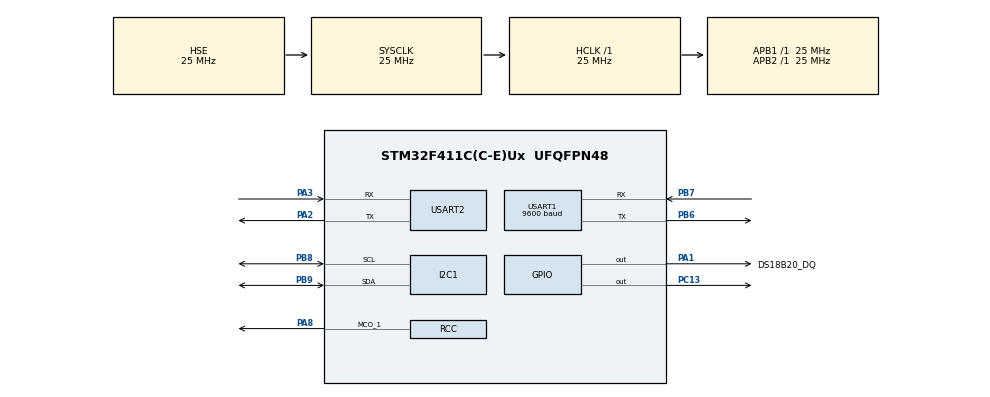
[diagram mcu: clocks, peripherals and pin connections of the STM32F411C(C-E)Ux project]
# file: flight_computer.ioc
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Mcu.Family=STM32F4
Mcu.Name=STM32F411C(C-E)Ux
Mcu.Package=UFQFPN48
NVIC.PriorityGroup=NVIC_PRIORITYGROUP_4
NVIC.USART1_IRQn=true\:5\:0\:false\:false\:true\:true\:true\:true
PA1.GPIO_Label=DS18B20_DQ
PA1.GPIO_ModeDefaultOutputPP=GPIO_MODE_OUTPUT_OD
PA1.GPIO_PuPd=GPIO_NOPULL
PA1.PinState=GPIO_PIN_SET
PA1.Signal=GPIO_Output
PA13.Mode=Serial_Wire
PA13.Signal=SYS_JTMS-SWDIO
PA14.Mode=Serial_Wire
PA14.Signal=SYS_JTCK-SWCLK
PA2.Mode=Asynchronous
PA2.Signal=USART2_TX
PA3.Mode=Asynchronous
PA3.Signal=USART2_RX
PA8.Mode=Clock-out-1
PA8.Signal=RCC_MCO_1
PB6.Mode=Asynchronous
PB6.Signal=USART1_TX
PB7.Mode=Asynchronous
PB7.Signal=USART1_RX
PB8.Mode=I2C
PB8.Signal=I2C1_SCL
PB9.Mode=I2C
PB9.Signal=I2C1_SDA
PC13-ANTI_TAMP.Signal=GPIO_Output
PC14-OSC32_IN.Mode=LSE-External-Oscillator
PC14-OSC32_IN.Signal=RCC_OSC32_IN
PC15-OSC32_OUT.Mode=LSE-External-Oscillator
PC15-OSC32_OUT.Signal=RCC_OSC32_OUT
PH0\ -\ OSC_IN.Mode=HSE-External-Oscillator
PH0\ -\ OSC_IN.Signal=RCC_OSC_IN
PH1\ -\ OSC_OUT.Mode=HSE-External-Oscillator
PH1\ -\ OSC_OUT.Signal=RCC_OSC_OUT
ProjectManager.HeapSize=0x200
ProjectManager.StackSize=0x400
ProjectManager.TargetToolchain=CMake
RCC.AHBFreq_Value=25000000
RCC.APB1Freq_Value=25000000
RCC.APB1TimFreq_Value=25000000
RCC.APB2Freq_Value=25000000
RCC.APB2TimFreq_Value=25000000
RCC.CortexFreq_Value=25000000
RCC.HCLKFreq_Value=25000000
RCC.HSE_VALUE=25000000
RCC.HSI_VALUE=16000000
RCC.RCC_MCO1Source=RCC_MCO1SOURCE_HSE
RCC.RCC_MCODiv1=RCC_MCODIV_3
RCC.RCC_RTC_Clock_Source=RCC_RTCCLKSOURCE_LSE
RCC.RCC_RTC_Clock_SourceVirtual=RCC_RTCCLKSOURCE_LSE
RCC.SYSCLKFreq_VALUE=25000000
RCC.SYSCLKSource=RCC_SYSCLKSOURCE_HSE
RCC.VCOOutputFreq_Value=192000000
USART1.BaudRate=9600
USART1.VirtualMode=VM_ASYNC
USART2.VirtualMode=VM_ASYNC
VP_RTC_VS_RTC_Activate.Mode=RTC_Enabled
board=custom

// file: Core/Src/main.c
/* USER CODE BEGIN Header */
/**
  ******************************************************************************
  * @file           : main.c
  * @brief          : ASTRA Flight Computer entry point
  ******************************************************************************
  * @attention
  *
  * Copyright (c) 2026 STMicroelectronics.
  * All rights reserved.
  *
  * This software is licensed under terms that can be found in the LICENSE file
  * in the root directory of this software component.
  * If no LICENSE file comes with this software, it is provided AS-IS.
  *
  ******************************************************************************
  */
/* USER CODE END Header */
#include "main.h"

/* USER CODE BEGIN Includes */
#include "app.h"
/* USER CODE END Includes */

I2C_HandleTypeDef hi2c1;
RTC_HandleTypeDef hrtc;
UART_HandleTypeDef huart1;
UART_HandleTypeDef huart2;

void SystemClock_Config(void);
static void MX_GPIO_Init(void);
static void MX_RTC_Init(void);
static void MX_USART1_UART_Init(void);
static void MX_I2C1_Init(void);
static void MX_USART2_UART_Init(void);

int main(void) {

    HAL_Init();

    SystemClock_Config();

    MX_GPIO_Init();
    MX_RTC_Init();
    MX_USART1_UART_Init();
    MX_I2C1_Init();
    MX_USART2_UART_Init();

    /* USER CODE BEGIN 2 */
    App_Init(&hi2c1, &hrtc, &huart1, &huart2);
    /* USER CODE END 2 */

    /* USER CODE BEGIN WHILE */
    while (1) {
        App_Process();
    }
    /* USER CODE END WHILE */

}

void SystemClock_Config(void)
{
  RCC_OscInitTypeDef RCC_OscInitStruct = {0};
  RCC_ClkInitTypeDef RCC_ClkInitStruct = {0};

  __HAL_RCC_PWR_CLK_ENABLE();
  __HAL_PWR_VOLTAGESCALING_CONFIG(PWR_REGULATOR_VOLTAGE_SCALE1);

  RCC_OscInitStruct.OscillatorType = RCC_OSCILLATORTYPE_HSE|RCC_OSCILLATORTYPE_LSE;
  RCC_OscInitStruct.HSEState = RCC_HSE_ON;
  RCC_OscInitStruct.LSEState = RCC_LSE_ON;
  RCC_OscInitStruct.PLL.PLLState = RCC_PLL_NONE;
  if (HAL_RCC_OscConfig(&RCC_OscInitStruct) != HAL_OK)
  {
    Error_Handler();
  }

  RCC_ClkInitStruct.ClockType = RCC_CLOCKTYPE_HCLK|RCC_CLOCKTYPE_SYSCLK
                              |RCC_CLOCKTYPE_PCLK1|RCC_CLOCKTYPE_PCLK2;
  RCC_ClkInitStruct.SYSCLKSource = RCC_SYSCLKSOURCE_HSE;
  RCC_ClkInitStruct.AHBCLKDivider = RCC_SYSCLK_DIV1;
  RCC_ClkInitStruct.APB1CLKDivider = RCC_HCLK_DIV1;
  RCC_ClkInitStruct.APB2CLKDivider = RCC_HCLK_DIV1;

  if (HAL_RCC_ClockConfig(&RCC_ClkInitStruct, FLASH_LATENCY_0) != HAL_OK)
  {
    Error_Handler();
  }
  HAL_RCC_MCOConfig(RCC_MCO1, RCC_MCO1SOURCE_HSE, RCC_MCODIV_3);
}

static void MX_I2C1_Init(void)
{
  hi2c1.Instance = I2C1;
  hi2c1.Init.ClockSpeed = 100000;
  hi2c1.Init.DutyCycle = I2C_DUTYCYCLE_2;
  hi2c1.Init.OwnAddress1 = 0;
  hi2c1.Init.AddressingMode = I2C_ADDRESSINGMODE_7BIT;
  hi2c1.Init.DualAddressMode = I2C_DUALADDRESS_DISABLE;
  hi2c1.Init.OwnAddress2 = 0;
  hi2c1.Init.GeneralCallMode = I2C_GENERALCALL_DISABLE;
  hi2c1.Init.NoStretchMode = I2C_NOSTRETCH_DISABLE;
  if (HAL_I2C_Init(&hi2c1) != HAL_OK)
  {
    Error_Handler();
  }
}

static void MX_RTC_Init(void)
{
  hrtc.Instance = RTC;
  hrtc.Init.HourFormat = RTC_HOURFORMAT_24;
  hrtc.Init.AsynchPrediv = 127;
  hrtc.Init.SynchPrediv = 255;
  hrtc.Init.OutPut = RTC_OUTPUT_DISABLE;
  hrtc.Init.OutPutPolarity = RTC_OUTPUT_POLARITY_HIGH;
  hrtc.Init.OutPutType = RTC_OUTPUT_TYPE_OPENDRAIN;
  if (HAL_RTC_Init(&hrtc) != HAL_OK)
  {
    Error_Handler();
  }
}

static void MX_USART1_UART_Init(void)
{
  huart1.Instance = USART1;
  huart1.Init.BaudRate = 9600;
  huart1.Init.WordLength = UART_WORDLENGTH_8B;
  huart1.Init.StopBits = UART_STOPBITS_1;
  huart1.Init.Parity = UART_PARITY_NONE;
  huart1.Init.Mode = UART_MODE_TX_RX;
  huart1.Init.HwFlowCtl = UART_HWCONTROL_NONE;
  huart1.Init.OverSampling = UART_OVERSAMPLING_16;
  if (HAL_UART_Init(&huart1) != HAL_OK)
  {
    Error_Handler();
  }
}

static void MX_USART2_UART_Init(void)
{
  huart2.Instance = USART2;
  huart2.Init.BaudRate = 115200;
  huart2.Init.WordLength = UART_WORDLENGTH_8B;
  huart2.Init.StopBits = UART_STOPBITS_1;
  huart2.Init.Parity = UART_PARITY_NONE;
  huart2.Init.Mode = UART_MODE_TX_RX;
  huart2.Init.HwFlowCtl = UART_HWCONTROL_NONE;
  huart2.Init.OverSampling = UART_OVERSAMPLING_16;
  if (HAL_UART_Init(&huart2) != HAL_OK)
  {
    Error_Handler();
  }
}

static void MX_GPIO_Init(void)
{
  GPIO_InitTypeDef GPIO_InitStruct = {0};

  __HAL_RCC_GPIOC_CLK_ENABLE();
  __HAL_RCC_GPIOH_CLK_ENABLE();
  __HAL_RCC_GPIOA_CLK_ENABLE();
  __HAL_RCC_GPIOB_CLK_ENABLE();

  HAL_GPIO_WritePin(GPIOC, GPIO_PIN_13, GPIO_PIN_RESET);
  HAL_GPIO_WritePin(DS18B20_DQ_GPIO_Port, DS18B20_DQ_Pin, GPIO_PIN_SET);

  GPIO_InitStruct.Pin = GPIO_PIN_13;
  GPIO_InitStruct.Mode = GPIO_MODE_OUTPUT_PP;
  GPIO_InitStruct.Pull = GPIO_NOPULL;
  GPIO_InitStruct.Speed = GPIO_SPEED_FREQ_LOW;
  HAL_GPIO_Init(GPIOC, &GPIO_InitStruct);

  GPIO_InitStruct.Pin = DS18B20_DQ_Pin;
  GPIO_InitStruct.Mode = GPIO_MODE_OUTPUT_OD;
  GPIO_InitStruct.Pull = GPIO_NOPULL;
  GPIO_InitStruct.Speed = GPIO_SPEED_FREQ_LOW;
  HAL_GPIO_Init(DS18B20_DQ_GPIO_Port, &GPIO_InitStruct);

  GPIO_InitStruct.Pin = GPIO_PIN_8;
  GPIO_InitStruct.Mode = GPIO_MODE_AF_PP;
  GPIO_InitStruct.Pull = GPIO_NOPULL;
  GPIO_InitStruct.Speed = GPIO_SPEED_FREQ_LOW;
  GPIO_InitStruct.Alternate = GPIO_AF0_MCO;
  HAL_GPIO_Init(GPIOA, &GPIO_InitStruct);
}

/* USER CODE BEGIN 4 */
/* USART2 is enabled here because CubeMX did not generate its IRQ wrapper. */
void USART2_IRQHandler(void) {
    HAL_UART_IRQHandler(&huart2);
}

void HAL_UART_TxCpltCallback(UART_HandleTypeDef *uart) {
    App_UartTxComplete(uart);
}

void HAL_UART_RxCpltCallback(UART_HandleTypeDef *uart) {
    App_UartRxComplete(uart);
}

void HAL_UART_ErrorCallback(UART_HandleTypeDef *uart) {
    App_UartError(uart);
}
/* USER CODE END 4 */

void Error_Handler(void)
{
  /* USER CODE BEGIN Error_Handler_Debug */
  /* Only non-recoverable MCU/peripheral infrastructure failures terminate here. */
  __disable_irq();
  while (1)
  {
  }
  /* USER CODE END Error_Handler_Debug */
}
